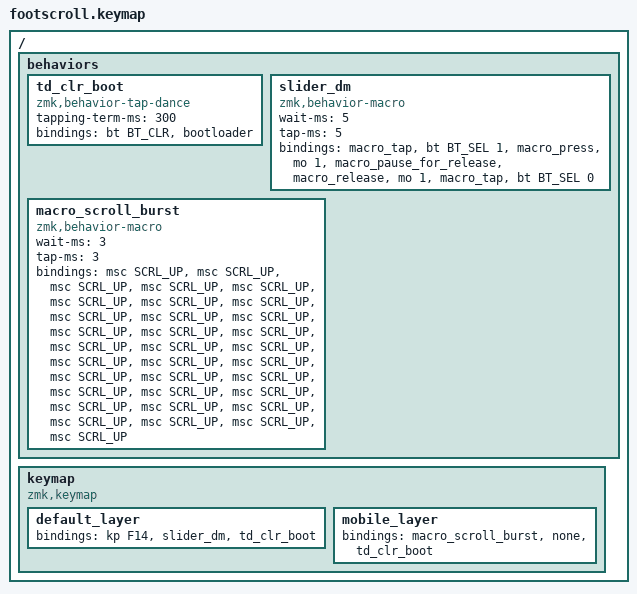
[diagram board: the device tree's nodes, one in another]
#include <behaviors.dtsi>
#include <dt-bindings/zmk/keys.h>
#include <dt-bindings/zmk/bt.h>
#include <dt-bindings/zmk/mouse.h>

/ {
    behaviors {
        td_clr_boot: td_clr_boot {
            compatible = "zmk,behavior-tap-dance";
            #binding-cells = <0>;
            tapping-term-ms = <300>;
            bindings = <&bt BT_CLR>, <&bootloader>;
        };

        // Slider: D=released(GPIO open)=desktop(F14, BT profile 0), M=engaged(GPIO closed)=mobile(scroll burst, BT profile 1)
        slider_dm: slider_dm {
            compatible = "zmk,behavior-macro";
            #binding-cells = <0>;
            wait-ms = <5>;
            tap-ms = <5>;
            bindings
                = <&macro_tap &bt BT_SEL 1>
                , <&macro_press &mo 1>
                , <&macro_pause_for_release>
                , <&macro_release &mo 1>
                , <&macro_tap &bt BT_SEL 0>
                ;
        };

        macro_scroll_burst: macro_scroll_burst {
            compatible = "zmk,behavior-macro";
            #binding-cells = <0>;
            wait-ms = <3>;
            tap-ms = <3>;
            bindings
                = <&msc SCRL_UP>, <&msc SCRL_UP>, <&msc SCRL_UP>
                , <&msc SCRL_UP>, <&msc SCRL_UP>, <&msc SCRL_UP>
                , <&msc SCRL_UP>, <&msc SCRL_UP>, <&msc SCRL_UP>
                , <&msc SCRL_UP>, <&msc SCRL_UP>, <&msc SCRL_UP>
                , <&msc SCRL_UP>, <&msc SCRL_UP>, <&msc SCRL_UP>
                , <&msc SCRL_UP>, <&msc SCRL_UP>, <&msc SCRL_UP>
                , <&msc SCRL_UP>, <&msc SCRL_UP>, <&msc SCRL_UP>
                , <&msc SCRL_UP>, <&msc SCRL_UP>, <&msc SCRL_UP>
                , <&msc SCRL_UP>, <&msc SCRL_UP>, <&msc SCRL_UP>
                , <&msc SCRL_UP>, <&msc SCRL_UP>, <&msc SCRL_UP>
                , <&msc SCRL_UP>, <&msc SCRL_UP>, <&msc SCRL_UP>
                ;
        };
    };

    keymap {
        compatible = "zmk,keymap";

        default_layer {
            bindings = <
                &kp F14
                &slider_dm
                &td_clr_boot
            >;
        };

        mobile_layer {
            bindings = <
                &macro_scroll_burst
                &none
                &td_clr_boot
            >;
        };
    };
};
